# D2522AA register map
Vendor: Dialog; Series: D2522AA; File version: 1.2
CPU: CM0 r1p0, little endian, MPU, FPU, 3 interrupt priority bits
Registers are 32-bit, read-write, reset 0x0 unless marked. A register's access mark holds for its fields unless they carry their own. Offsets are from the block's base; [hi:lo] are bit positions; {n}, {i} and the like mark numbered series.

## MEMCTRL — MEMCTRL registers
Base 0x50050000
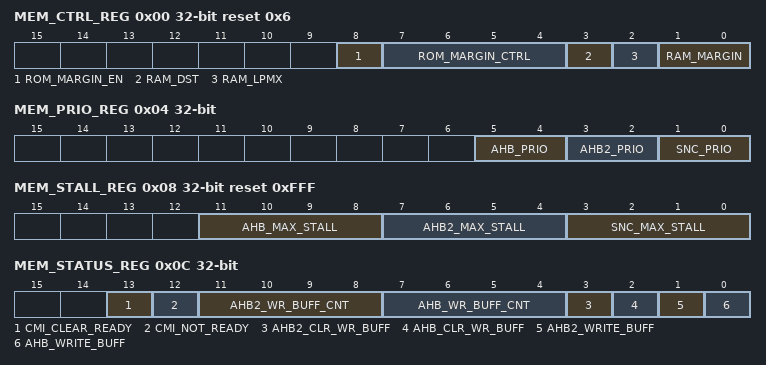
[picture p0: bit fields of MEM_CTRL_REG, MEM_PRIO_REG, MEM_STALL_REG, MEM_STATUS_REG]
0x00 MEM_CTRL_REG reset 0x6
  [8] ROM_MARGIN_EN — ROM read and write margin enable.
  [7:4] ROM_MARGIN_CTRL — ROM read and write margin control.
  [3] RAM_DST — RAM Disable-Self-Time. When asserted high, overrides the self-timed circuitry and causes the read margin to be controlled by the falling clock edge. Requires RAM_MARGIN to be set to "00".
  [2] RAM_LPMX — RAM Transparent Light Sleep (TLS) Core Enable. Assert low to enable the TLS core feature, which will result in lower leakage current. It is required to power-on with this pin high (disabled) until the VDD supply is stable. In case VDD is lowered below nominal-10%, it may be necessary to hold this pin high to maintain data retention.
  [1:0] RAM_MARGIN — RAM read and write margin control. Setting "10" is recommended. 00: Provides the most margin (slowest speed). 11: Provides the least margin (fastest speed).
0x04 MEM_PRIO_REG
  [5:4] AHB_PRIO, [3:2] AHB2_PRIO, [1:0] SNC_PRIO
0x08 MEM_STALL_REG reset 0xFFF
  [11:8] AHB_MAX_STALL, [7:4] AHB2_MAX_STALL, [3:0] SNC_MAX_STALL
0x0C MEM_STATUS_REG
  [13] CMI_CLEAR_READY wo, [12] CMI_NOT_READY ro, [11:8] AHB2_WR_BUFF_CNT ro, [7:4] AHB_WR_BUFF_CNT ro, [3] AHB2_CLR_WR_BUFF wo, [2] AHB_CLR_WR_BUFF wo, [1] AHB2_WRITE_BUFF ro, [0] AHB_WRITE_BUFF ro
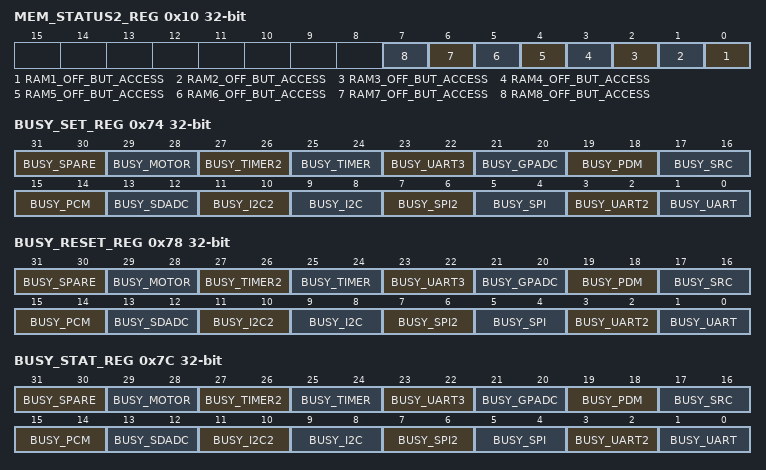
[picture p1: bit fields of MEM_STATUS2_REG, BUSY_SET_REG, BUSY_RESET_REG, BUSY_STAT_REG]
0x10 MEM_STATUS2_REG
  [n-1] RAM{n}_OFF_BUT_ACCESS (n=1..8)
0x20 CMI_CODE_BASE_REG
  [18:10] CMI_CODE_BASE_ADDR — Base address for CMAC code with steps of 1 kB. 0x001: 1 kB base address 0x010: 16 kB base address 0x100: 256 kB base address
0x24 CMI_DATA_BASE_REG
  [18:2] CMI_DATA_BASE_ADDR — Base address for CMAC data with steps of 4 bytes. 0x00001: 4 byte base address 0x00010: 64 byte base address 0x00100: 1 kB base address 0x01000: 16 kB base address 0x10000: 256 kB base address
0x28 CMI_SHARED_BASE_REG
  [18:10] CMI_SHARED_BASE_ADDR — Base address for CMAC shared data with steps of 1 kB. 0x001: 1 kB base address 0x010: 16 kB base address 0x100: 256 kB base address
0x2C CMI_END_REG reset 0x7FFFF
  [18:10] CMI_END_ADDR — End address for CMAC code and data accesses with steps of 1 kB. 0x000: accesses up to 1kB are allowed 0x001: accesses up to 2kB are allowed 0x01F: accesses up to 32kB are allowed 0x1FF: accesses up to 512kB are allowed
0x30 SNC_BASE_REG
  [18:2] SNC_BASE_ADDRESS — Base address for SNC interface with steps of 4 bytes. 0x00001: 4 byte base address 0x00010: 64 byte base address 0x00100: 1 kB base address 0x01000: 16 kB base address 0x10000: 256 kB base address
0x74 BUSY_SET_REG (reset mask 0x7FFFFFFF)
  [31:30] BUSY_SPARE write-once — Writing a non-zero value to this field sets the corresponding BUSY bit, but only if it was not claimed (BUSY=0). Reading returns 0 to allow read/modify/write to the register.
  [29:28] BUSY_MOTOR write-once — Writing a non-zero value to this field sets the corresponding BUSY bit, but only if it was not claimed (BUSY=0). Reading returns 0 to allow read/modify/write to the register.
  [27:26] BUSY_TIMER2 write-once — Writing a non-zero value to this field sets the corresponding BUSY bit, but only if it was not claimed (BUSY=0). Reading returns 0 to allow read/modify/write to the register.
  [25:24] BUSY_TIMER write-once — Writing a non-zero value to this field sets the corresponding BUSY bit, but only if it was not claimed (BUSY=0). Reading returns 0 to allow read/modify/write to the register.
  [23:22] BUSY_UART3 write-once — Writing a non-zero value to this field sets the corresponding BUSY bit, but only if it was not claimed (BUSY=0). Reading returns 0 to allow read/modify/write to the register.
  [21:20] BUSY_GPADC write-once — Writing a non-zero value to this field sets the corresponding BUSY bit, but only if it was not claimed (BUSY=0). Reading returns 0 to allow read/modify/write to the register.
  [19:18] BUSY_PDM write-once — Writing a non-zero value to this field sets the corresponding BUSY bit, but only if it was not claimed (BUSY=0). Reading returns 0 to allow read/modify/write to the register.
  [17:16] BUSY_SRC write-once — Writing a non-zero value to this field sets the corresponding BUSY bit, but only if it was not claimed (BUSY=0). Reading returns 0 to allow read/modify/write to the register.
  [15:14] BUSY_PCM write-once — Writing a non-zero value to this field sets the corresponding BUSY bit, but only if it was not claimed (BUSY=0). Reading returns 0 to allow read/modify/write to the register.
  [13:12] BUSY_SDADC write-once — Writing a non-zero value to this field sets the corresponding BUSY bit, but only if it was not claimed (BUSY=0). Reading returns 0 to allow read/modify/write to the register.
  [11:10] BUSY_I2C2 write-once — Writing a non-zero value to this field sets the corresponding BUSY bit, but only if it was not claimed (BUSY=0). Reading returns 0 to allow read/modify/write to the register.
  [9:8] BUSY_I2C write-once — Writing a non-zero value to this field sets the corresponding BUSY bit, but only if it was not claimed (BUSY=0). Reading returns 0 to allow read/modify/write to the register.
  [7:6] BUSY_SPI2 write-once — Writing a non-zero value to this field sets the corresponding BUSY bit, but only if it was not claimed (BUSY=0). Reading returns 0 to allow read/modify/write to the register.
  [5:4] BUSY_SPI write-once — Writing a non-zero value to this field sets the corresponding BUSY bit, but only if it was not claimed (BUSY=0). Reading returns 0 to allow read/modify/write to the register.
  [3:2] BUSY_UART2 write-once — Writing a non-zero value to this field sets the corresponding BUSY bit, but only if it was not claimed (BUSY=0). Reading returns 0 to allow read/modify/write to the register.
  [1:0] BUSY_UART write-once — Writing a non-zero value to this field sets the corresponding BUSY bit, but only if it was not claimed (BUSY=0). Reading returns 0 to allow read/modify/write to the register.
0x78 BUSY_RESET_REG (reset mask 0x7FFFFFFF)
  [31:30] BUSY_SPARE — Clear the BUSY bitfield, by writing the master code which has claimed to this field Reading returns 0 to allow read/modify/write to the register.
  [29:28] BUSY_MOTOR — Clear the BUSY bitfield, by writing the master code which has claimed to this field Reading returns 0 to allow read/modify/write to the register.
  [27:26] BUSY_TIMER2 — Clear the BUSY bitfield, by writing the master code which has claimed to this field Reading returns 0 to allow read/modify/write to the register.
  [25:24] BUSY_TIMER — Clear the BUSY bitfield, by writing the master code which has claimed to this field Reading returns 0 to allow read/modify/write to the register.
  [23:22] BUSY_UART3 — Clear the BUSY bitfield, by writing the master code which has claimed to this field Reading returns 0 to allow read/modify/write to the register.
  [21:20] BUSY_GPADC — Clear the BUSY bitfield, by writing the master code which has claimed to this field Reading returns 0 to allow read/modify/write to the register.
  [19:18] BUSY_PDM — Clear the BUSY bitfield, by writing the master code which has claimed to this field Reading returns 0 to allow read/modify/write to the register.
  [17:16] BUSY_SRC — Clear the BUSY bitfield, by writing the master code which has claimed to this field Reading returns 0 to allow read/modify/write to the register.
  [15:14] BUSY_PCM — Clear the BUSY bitfield, by writing the master code which has claimed to this field Reading returns 0 to allow read/modify/write to the register.
  [13:12] BUSY_SDADC — Clear the BUSY bitfield, by writing the master code which has claimed to this field Reading returns 0 to allow read/modify/write to the register.
  [11:10] BUSY_I2C2 — Clear the BUSY bitfield, by writing the master code which has claimed to this field Reading returns 0 to allow read/modify/write to the register.
  [9:8] BUSY_I2C — Clear the BUSY bitfield, by writing the master code which has claimed to this field Reading returns 0 to allow read/modify/write to the register.
  [7:6] BUSY_SPI2 — Clear the BUSY bitfield, by writing the master code which has claimed to this field Reading returns 0 to allow read/modify/write to the register.
  [5:4] BUSY_SPI — Clear the BUSY bitfield, by writing the master code which has claimed to this field Reading returns 0 to allow read/modify/write to the register.
  [3:2] BUSY_UART2 — Clear the BUSY bitfield, by writing the master code which has claimed to this field Reading returns 0 to allow read/modify/write to the register.
  [1:0] BUSY_UART — Clear the BUSY bitfield, by writing the master code which has claimed to this field Reading returns 0 to allow read/modify/write to the register.
0x7C BUSY_STAT_REG (reset mask 0x7FFFFFFF)
  [31:30] BUSY_SPARE ro — A non-zero value indicates the resource is busy. The value represents which master is using it.
  [29:28] BUSY_MOTOR ro — A non-zero value indicates the resource is busy. The value represents which master is using it.
  [27:26] BUSY_TIMER2 ro — A non-zero value indicates the resource is busy. The value represents which master is using it.
  [25:24] BUSY_TIMER ro — A non-zero value indicates the resource is busy. The value represents which master is using it.
  [23:22] BUSY_UART3 ro — A non-zero value indicates the resource is busy. The value represents which master is using it.
  [21:20] BUSY_GPADC ro — A non-zero value indicates the resource is busy. The value represents which master is using it.
  [19:18] BUSY_PDM ro — A non-zero value indicates the resource is busy. The value represents which master is using it.
  [17:16] BUSY_SRC ro — A non-zero value indicates the resource is busy. The value represents which master is using it.
  [15:14] BUSY_PCM ro — A non-zero value indicates the resource is busy. The value represents which master is using it.
  [13:12] BUSY_SDADC ro — A non-zero value indicates the resource is busy. The value represents which master is using it.
  [11:10] BUSY_I2C2 ro — A non-zero value indicates the resource is busy. The value represents which master is using it.
  [9:8] BUSY_I2C ro — A non-zero value indicates the resource is busy. The value represents which master is using it.
  [7:6] BUSY_SPI2 ro — A non-zero value indicates the resource is busy. The value represents which master is using it.
  [5:4] BUSY_SPI ro — A non-zero value indicates the resource is busy. The value represents which master is using it.
  [3:2] BUSY_UART2 ro — A non-zero value indicates the resource is busy. The value represents which master is using it.
  [1:0] BUSY_UART ro — A non-zero value indicates the resource is busy. The value represents which master is using it.
